# iorx62n register map
Registers are 8-bit, access not given, no defined reset value unless marked. A register's access mark holds for its fields unless they carry their own. Addresses are absolute; registers are grouped by the start of their names; [hi:lo] are bit positions; {n}, {i} and the like mark numbered series; 'fields as' and 'values as' point back to an identical list.

## SFR (part 2 of 3)
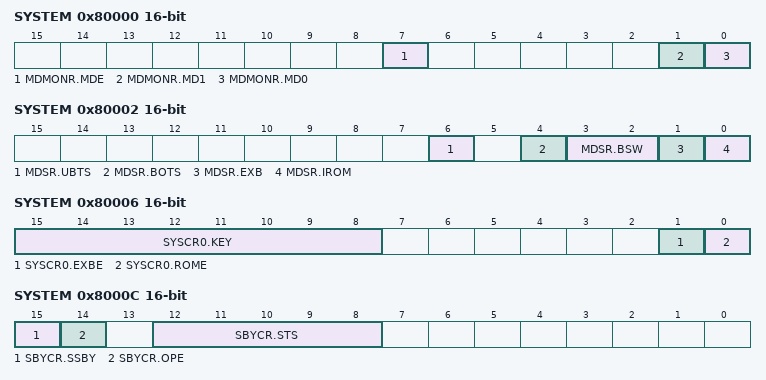
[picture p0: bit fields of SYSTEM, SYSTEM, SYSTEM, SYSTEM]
0x80000 SYSTEM 16-bit
  [7] MDMONR.MDE, [1] MDMONR.MD1, [0] MDMONR.MD0
0x80002 SYSTEM 16-bit
  [6] MDSR.UBTS, [4] MDSR.BOTS, [3:2] MDSR.BSW, [1] MDSR.EXB, [0] MDSR.IROM
0x80006 SYSTEM 16-bit
  [15:8] SYSCR0.KEY, [1] SYSCR0.EXBE, [0] SYSCR0.ROME
0x80008 SYSTEM 16-bit
  [0] SYSCR1.RAME
0x8000C SYSTEM 16-bit
  [15] SBYCR.SSBY, [14] SBYCR.OPE, [12:8] SBYCR.STS
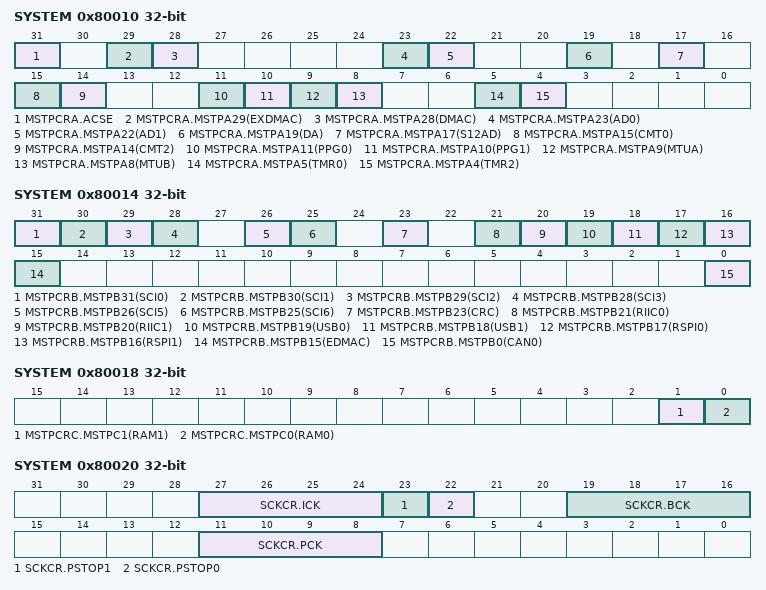
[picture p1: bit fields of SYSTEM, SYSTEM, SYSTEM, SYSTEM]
0x80010 SYSTEM 32-bit
  [31] MSTPCRA.ACSE, [29] MSTPCRA.MSTPA29(EXDMAC), [28] MSTPCRA.MSTPA28(DMAC), [23] MSTPCRA.MSTPA23(AD0), [22] MSTPCRA.MSTPA22(AD1), [19] MSTPCRA.MSTPA19(DA), [17] MSTPCRA.MSTPA17(S12AD), [15] MSTPCRA.MSTPA15(CMT0), [14] MSTPCRA.MSTPA14(CMT2), [11] MSTPCRA.MSTPA11(PPG0), [10] MSTPCRA.MSTPA10(PPG1), [9] MSTPCRA.MSTPA9(MTUA), [8] MSTPCRA.MSTPA8(MTUB), [5] MSTPCRA.MSTPA5(TMR0), [4] MSTPCRA.MSTPA4(TMR2)
0x80014 SYSTEM 32-bit
  [31] MSTPCRB.MSTPB31(SCI0), [30] MSTPCRB.MSTPB30(SCI1), [29] MSTPCRB.MSTPB29(SCI2), [28] MSTPCRB.MSTPB28(SCI3), [26] MSTPCRB.MSTPB26(SCI5), [25] MSTPCRB.MSTPB25(SCI6), [23] MSTPCRB.MSTPB23(CRC), [21] MSTPCRB.MSTPB21(RIIC0), [20] MSTPCRB.MSTPB20(RIIC1), [19] MSTPCRB.MSTPB19(USB0), [18] MSTPCRB.MSTPB18(USB1), [17] MSTPCRB.MSTPB17(RSPI0), [16] MSTPCRB.MSTPB16(RSPI1), [15] MSTPCRB.MSTPB15(EDMAC), [0] MSTPCRB.MSTPB0(CAN0)
0x80018 SYSTEM 32-bit
  [1] MSTPCRC.MSTPC1(RAM1), [0] MSTPCRC.MSTPC0(RAM0)
0x80020 SYSTEM 32-bit
  [27:24] SCKCR.ICK, [23] SCKCR.PSTOP1, [22] SCKCR.PSTOP0, [19:16] SCKCR.BCK, [11:8] SCKCR.PCK
0x80030 SYSTEM
  [0] BCKCR.BCLKDIV
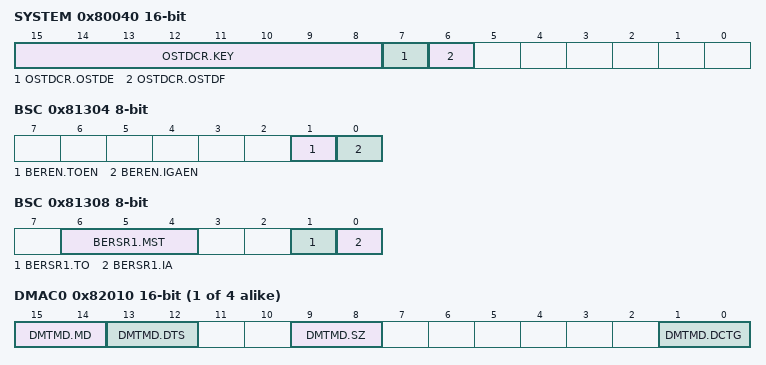
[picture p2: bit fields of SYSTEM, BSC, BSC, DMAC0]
0x80040 SYSTEM 16-bit
  [15:8] OSTDCR.KEY, [7] OSTDCR.OSTDE, [6] OSTDCR.OSTDF
0x81300 BSC
  [0] BERCLR.STSCLR
0x81304 BSC
  [1] BEREN.TOEN, [0] BEREN.IGAEN
0x81308 BSC
  [6:4] BERSR1.MST, [1] BERSR1.TO, [0] BERSR1.IA
0x8130A BSC 16-bit
  [15:3] BERSR2.ADDR
{0x82010+0x40*i} DMAC{i} 16-bit (i=0..3)
  [15:14] DMTMD.MD, [13:12] DMTMD.DTS, [9:8] DMTMD.SZ, [1:0] DMTMD.DCTG
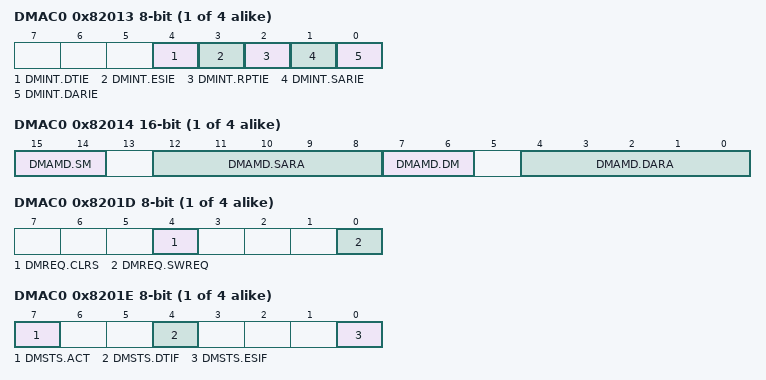
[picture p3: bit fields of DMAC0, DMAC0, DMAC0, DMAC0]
{0x82013+0x40*i} DMAC{i} (i=0..3)
  [4] DMINT.DTIE, [3] DMINT.ESIE, [2] DMINT.RPTIE, [1] DMINT.SARIE, [0] DMINT.DARIE
{0x82014+0x40*i} DMAC{i} 16-bit (i=0..3)
  [15:14] DMAMD.SM, [12:8] DMAMD.SARA, [7:6] DMAMD.DM, [4:0] DMAMD.DARA
{0x8201C+0x40*i} DMAC{i} (i=0..3)
  [0] DMCNT.DTE
{0x8201D+0x40*i} DMAC{i} (i=0..3)
  [4] DMREQ.CLRS, [0] DMREQ.SWREQ
{0x8201E+0x40*i} DMAC{i} (i=0..3)
  [7] DMSTS.ACT, [4] DMSTS.DTIF, [0] DMSTS.ESIF
{0x8201F+0x40*i} DMAC{i} (i=0..3)
  [0] DMCSL.DISEL
0x82200 DMAC
  [0] DMAST.DMST
0x82400 DTC
  [4] DTCCR.RRS
0x82408 DTC
  [0] DTCADMOD.SHORT
0x8240C DTC
  [0] DTCST.DTCST
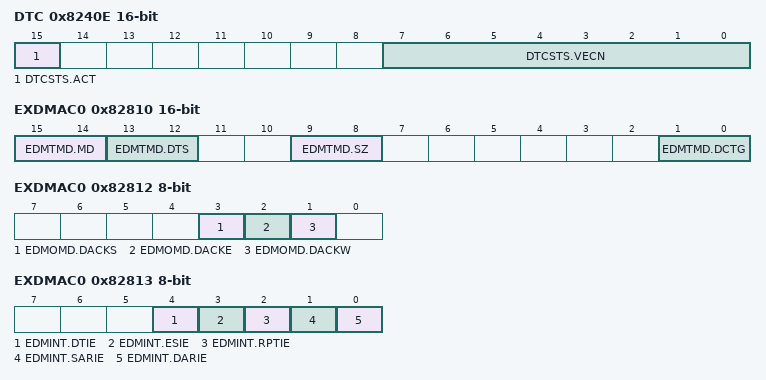
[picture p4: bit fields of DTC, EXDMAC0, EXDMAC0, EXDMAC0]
0x8240E DTC 16-bit
  [15] DTCSTS.ACT, [7:0] DTCSTS.VECN
0x82810 EXDMAC0 16-bit
  [15:14] EDMTMD.MD, [13:12] EDMTMD.DTS, [9:8] EDMTMD.SZ, [1:0] EDMTMD.DCTG
0x82812 EXDMAC0
  [3] EDMOMD.DACKS, [2] EDMOMD.DACKE, [1] EDMOMD.DACKW
0x82813 EXDMAC0
  [4] EDMINT.DTIE, [3] EDMINT.ESIE, [2] EDMINT.RPTIE, [1] EDMINT.SARIE, [0] EDMINT.DARIE
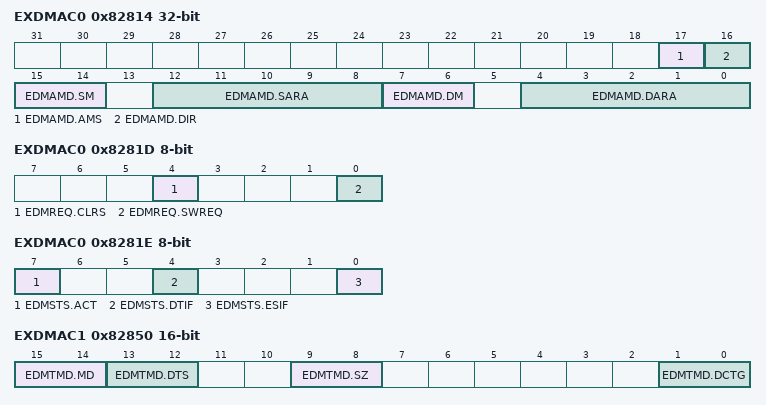
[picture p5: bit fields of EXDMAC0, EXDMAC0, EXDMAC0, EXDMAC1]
0x82814 EXDMAC0 32-bit
  [17] EDMAMD.AMS, [16] EDMAMD.DIR, [15:14] EDMAMD.SM, [12:8] EDMAMD.SARA, [7:6] EDMAMD.DM, [4:0] EDMAMD.DARA
0x8281C EXDMAC0
  [0] EDMCNT.DTE
0x8281D EXDMAC0
  [4] EDMREQ.CLRS, [0] EDMREQ.SWREQ
0x8281E EXDMAC0
  [7] EDMSTS.ACT, [4] EDMSTS.DTIF, [0] EDMSTS.ESIF
0x82820 EXDMAC0
  [1:0] EDMRMD.DREQS
0x82821 EXDMAC0
  [0] EDMERF.EREQ
0x82822 EXDMAC0
  [0] EDMPRF.PREQ
0x82850 EXDMAC1 16-bit
  fields as EXDMAC0
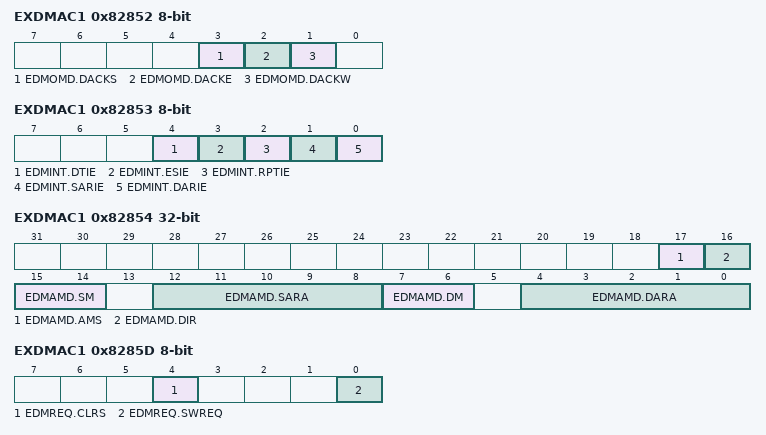
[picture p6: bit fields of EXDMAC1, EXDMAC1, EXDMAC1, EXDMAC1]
0x82852 EXDMAC1
  [3] EDMOMD.DACKS, [2] EDMOMD.DACKE, [1] EDMOMD.DACKW
0x82853 EXDMAC1
  [4] EDMINT.DTIE, [3] EDMINT.ESIE, [2] EDMINT.RPTIE, [1] EDMINT.SARIE, [0] EDMINT.DARIE
0x82854 EXDMAC1 32-bit
  [17] EDMAMD.AMS, [16] EDMAMD.DIR, [15:14] EDMAMD.SM, [12:8] EDMAMD.SARA, [7:6] EDMAMD.DM, [4:0] EDMAMD.DARA
0x8285C EXDMAC1
  [0] EDMCNT.DTE
0x8285D EXDMAC1
  [4] EDMREQ.CLRS, [0] EDMREQ.SWREQ
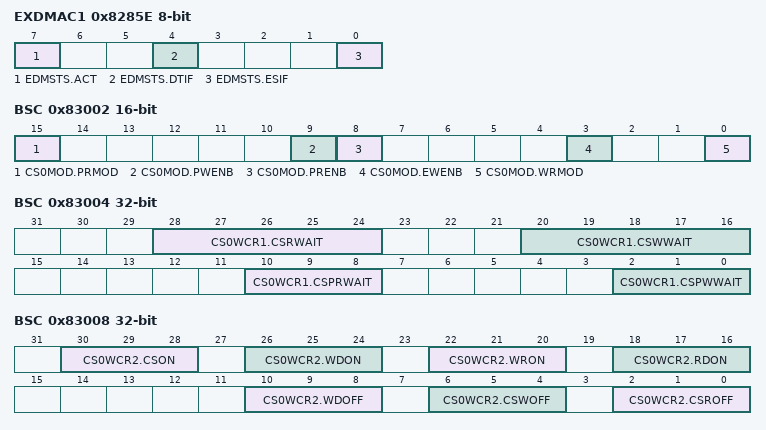
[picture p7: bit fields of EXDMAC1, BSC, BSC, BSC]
0x8285E EXDMAC1
  [7] EDMSTS.ACT, [4] EDMSTS.DTIF, [0] EDMSTS.ESIF
0x82860 EXDMAC1
  [1:0] EDMRMD.DREQS
0x82861 EXDMAC1
  [0] EDMERF.EREQ
0x82862 EXDMAC1
  [0] EDMPRF.PREQ
0x82A00 EXDMAC
  [0] EDMAST.DMST
0x83002 BSC 16-bit
  [15] CS0MOD.PRMOD, [9] CS0MOD.PWENB, [8] CS0MOD.PRENB, [3] CS0MOD.EWENB, [0] CS0MOD.WRMOD
0x83004 BSC 32-bit
  [28:24] CS0WCR1.CSRWAIT, [20:16] CS0WCR1.CSWWAIT, [10:8] CS0WCR1.CSPRWAIT, [2:0] CS0WCR1.CSPWWAIT
0x83008 BSC 32-bit
  [30:28] CS0WCR2.CSON, [26:24] CS0WCR2.WDON, [22:20] CS0WCR2.WRON, [18:16] CS0WCR2.RDON, [10:8] CS0WCR2.WDOFF, [6:4] CS0WCR2.CSWOFF, [2:0] CS0WCR2.CSROFF
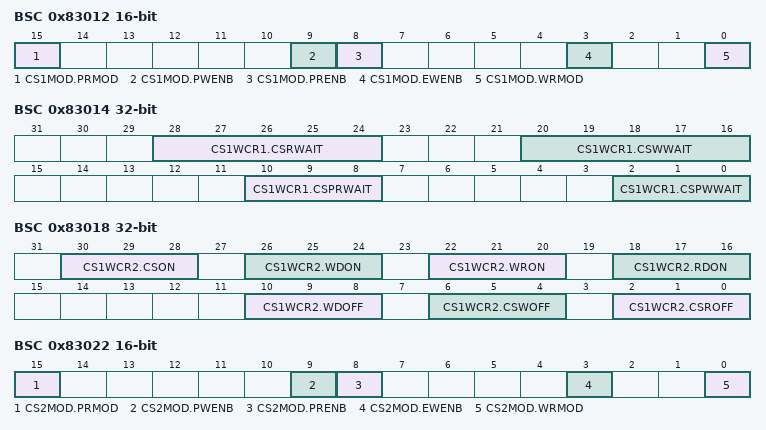
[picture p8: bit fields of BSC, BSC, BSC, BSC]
0x83012 BSC 16-bit
  [15] CS1MOD.PRMOD, [9] CS1MOD.PWENB, [8] CS1MOD.PRENB, [3] CS1MOD.EWENB, [0] CS1MOD.WRMOD
0x83014 BSC 32-bit
  [28:24] CS1WCR1.CSRWAIT, [20:16] CS1WCR1.CSWWAIT, [10:8] CS1WCR1.CSPRWAIT, [2:0] CS1WCR1.CSPWWAIT
0x83018 BSC 32-bit
  [30:28] CS1WCR2.CSON, [26:24] CS1WCR2.WDON, [22:20] CS1WCR2.WRON, [18:16] CS1WCR2.RDON, [10:8] CS1WCR2.WDOFF, [6:4] CS1WCR2.CSWOFF, [2:0] CS1WCR2.CSROFF
0x83022 BSC 16-bit
  [15] CS2MOD.PRMOD, [9] CS2MOD.PWENB, [8] CS2MOD.PRENB, [3] CS2MOD.EWENB, [0] CS2MOD.WRMOD
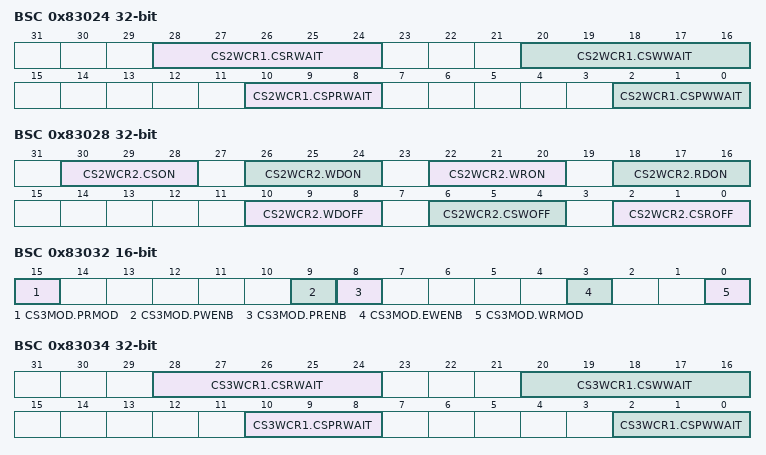
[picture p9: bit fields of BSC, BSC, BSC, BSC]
0x83024 BSC 32-bit
  [28:24] CS2WCR1.CSRWAIT, [20:16] CS2WCR1.CSWWAIT, [10:8] CS2WCR1.CSPRWAIT, [2:0] CS2WCR1.CSPWWAIT
0x83028 BSC 32-bit
  [30:28] CS2WCR2.CSON, [26:24] CS2WCR2.WDON, [22:20] CS2WCR2.WRON, [18:16] CS2WCR2.RDON, [10:8] CS2WCR2.WDOFF, [6:4] CS2WCR2.CSWOFF, [2:0] CS2WCR2.CSROFF
0x83032 BSC 16-bit
  [15] CS3MOD.PRMOD, [9] CS3MOD.PWENB, [8] CS3MOD.PRENB, [3] CS3MOD.EWENB, [0] CS3MOD.WRMOD
0x83034 BSC 32-bit
  [28:24] CS3WCR1.CSRWAIT, [20:16] CS3WCR1.CSWWAIT, [10:8] CS3WCR1.CSPRWAIT, [2:0] CS3WCR1.CSPWWAIT
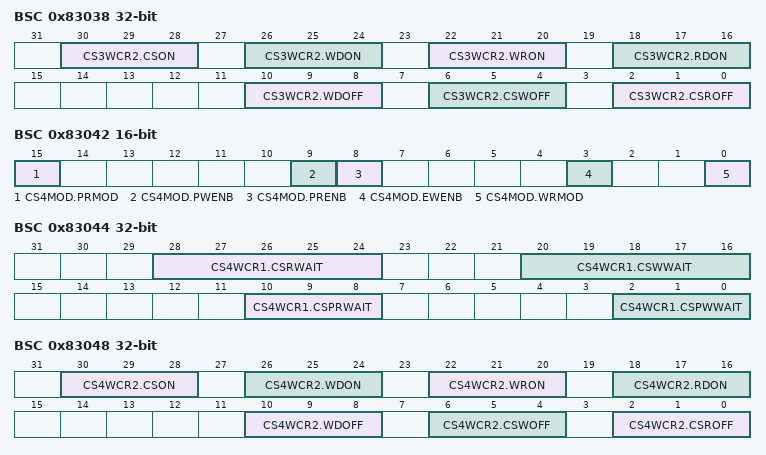
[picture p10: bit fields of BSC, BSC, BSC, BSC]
0x83038 BSC 32-bit
  [30:28] CS3WCR2.CSON, [26:24] CS3WCR2.WDON, [22:20] CS3WCR2.WRON, [18:16] CS3WCR2.RDON, [10:8] CS3WCR2.WDOFF, [6:4] CS3WCR2.CSWOFF, [2:0] CS3WCR2.CSROFF
0x83042 BSC 16-bit
  [15] CS4MOD.PRMOD, [9] CS4MOD.PWENB, [8] CS4MOD.PRENB, [3] CS4MOD.EWENB, [0] CS4MOD.WRMOD
0x83044 BSC 32-bit
  [28:24] CS4WCR1.CSRWAIT, [20:16] CS4WCR1.CSWWAIT, [10:8] CS4WCR1.CSPRWAIT, [2:0] CS4WCR1.CSPWWAIT
0x83048 BSC 32-bit
  [30:28] CS4WCR2.CSON, [26:24] CS4WCR2.WDON, [22:20] CS4WCR2.WRON, [18:16] CS4WCR2.RDON, [10:8] CS4WCR2.WDOFF, [6:4] CS4WCR2.CSWOFF, [2:0] CS4WCR2.CSROFF
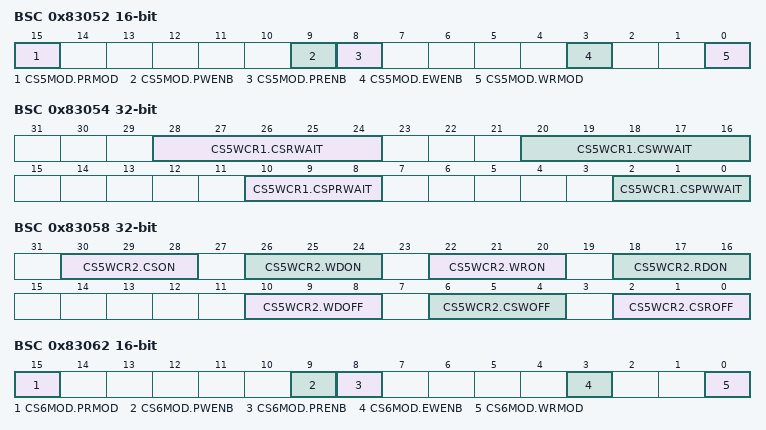
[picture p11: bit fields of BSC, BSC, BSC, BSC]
0x83052 BSC 16-bit
  [15] CS5MOD.PRMOD, [9] CS5MOD.PWENB, [8] CS5MOD.PRENB, [3] CS5MOD.EWENB, [0] CS5MOD.WRMOD
0x83054 BSC 32-bit
  [28:24] CS5WCR1.CSRWAIT, [20:16] CS5WCR1.CSWWAIT, [10:8] CS5WCR1.CSPRWAIT, [2:0] CS5WCR1.CSPWWAIT
0x83058 BSC 32-bit
  [30:28] CS5WCR2.CSON, [26:24] CS5WCR2.WDON, [22:20] CS5WCR2.WRON, [18:16] CS5WCR2.RDON, [10:8] CS5WCR2.WDOFF, [6:4] CS5WCR2.CSWOFF, [2:0] CS5WCR2.CSROFF
0x83062 BSC 16-bit
  [15] CS6MOD.PRMOD, [9] CS6MOD.PWENB, [8] CS6MOD.PRENB, [3] CS6MOD.EWENB, [0] CS6MOD.WRMOD
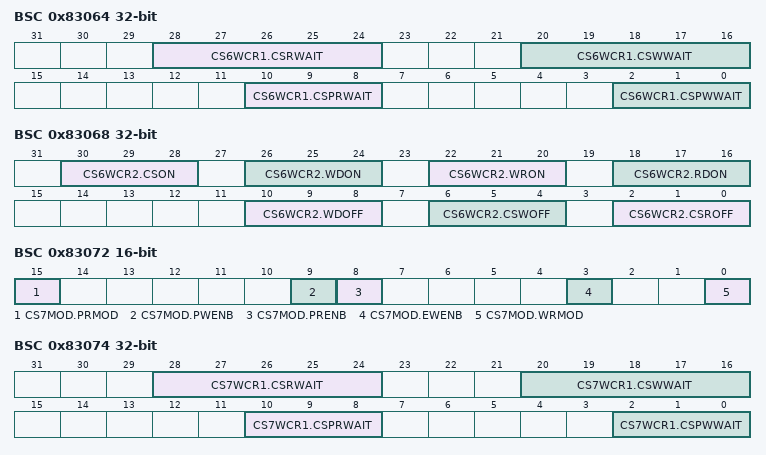
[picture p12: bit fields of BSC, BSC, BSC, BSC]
0x83064 BSC 32-bit
  [28:24] CS6WCR1.CSRWAIT, [20:16] CS6WCR1.CSWWAIT, [10:8] CS6WCR1.CSPRWAIT, [2:0] CS6WCR1.CSPWWAIT
0x83068 BSC 32-bit
  [30:28] CS6WCR2.CSON, [26:24] CS6WCR2.WDON, [22:20] CS6WCR2.WRON, [18:16] CS6WCR2.RDON, [10:8] CS6WCR2.WDOFF, [6:4] CS6WCR2.CSWOFF, [2:0] CS6WCR2.CSROFF
0x83072 BSC 16-bit
  [15] CS7MOD.PRMOD, [9] CS7MOD.PWENB, [8] CS7MOD.PRENB, [3] CS7MOD.EWENB, [0] CS7MOD.WRMOD
0x83074 BSC 32-bit
  [28:24] CS7WCR1.CSRWAIT, [20:16] CS7WCR1.CSWWAIT, [10:8] CS7WCR1.CSPRWAIT, [2:0] CS7WCR1.CSPWWAIT
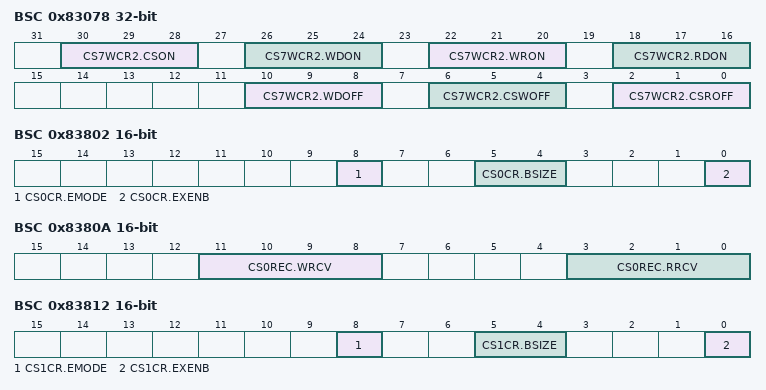
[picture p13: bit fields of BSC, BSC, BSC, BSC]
0x83078 BSC 32-bit
  [30:28] CS7WCR2.CSON, [26:24] CS7WCR2.WDON, [22:20] CS7WCR2.WRON, [18:16] CS7WCR2.RDON, [10:8] CS7WCR2.WDOFF, [6:4] CS7WCR2.CSWOFF, [2:0] CS7WCR2.CSROFF
0x83802 BSC 16-bit
  [8] CS0CR.EMODE, [5:4] CS0CR.BSIZE, [0] CS0CR.EXENB
0x8380A BSC 16-bit
  [11:8] CS0REC.WRCV, [3:0] CS0REC.RRCV
0x83812 BSC 16-bit
  [8] CS1CR.EMODE, [5:4] CS1CR.BSIZE, [0] CS1CR.EXENB
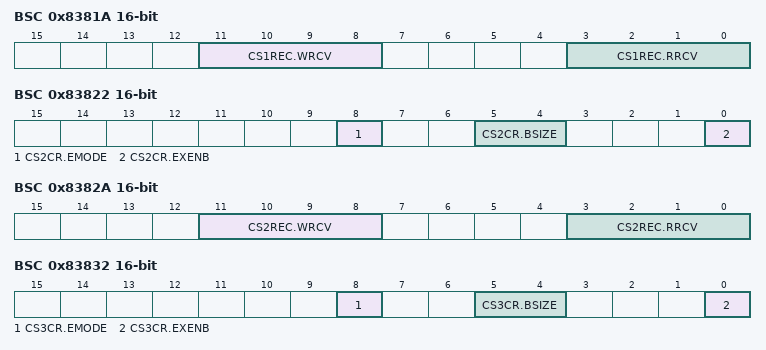
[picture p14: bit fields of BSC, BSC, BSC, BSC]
0x8381A BSC 16-bit
  [11:8] CS1REC.WRCV, [3:0] CS1REC.RRCV
0x83822 BSC 16-bit
  [8] CS2CR.EMODE, [5:4] CS2CR.BSIZE, [0] CS2CR.EXENB
0x8382A BSC 16-bit
  [11:8] CS2REC.WRCV, [3:0] CS2REC.RRCV
0x83832 BSC 16-bit
  [8] CS3CR.EMODE, [5:4] CS3CR.BSIZE, [0] CS3CR.EXENB
0x8383A BSC 16-bit
  [11:8] CS3REC.WRCV, [3:0] CS3REC.RRCV
0x83842 BSC 16-bit
  [8] CS4CR.EMODE, [5:4] CS4CR.BSIZE, [0] CS4CR.EXENB
0x8384A BSC 16-bit
  [11:8] CS4REC.WRCV, [3:0] CS4REC.RRCV
0x83852 BSC 16-bit
  [8] CS5CR.EMODE, [5:4] CS5CR.BSIZE, [0] CS5CR.EXENB
0x8385A BSC 16-bit
  [11:8] CS5REC.WRCV, [3:0] CS5REC.RRCV
0x83862 BSC 16-bit
  [8] CS6CR.EMODE, [5:4] CS6CR.BSIZE, [0] CS6CR.EXENB
0x8386A BSC 16-bit
  [11:8] CS6REC.WRCV, [3:0] CS6REC.RRCV
0x83872 BSC 16-bit
  [8] CS7CR.EMODE, [5:4] CS7CR.BSIZE, [0] CS7CR.EXENB
0x8387A BSC 16-bit
  [11:8] CS7REC.WRCV, [3:0] CS7REC.RRCV
0x83C00 BSC
  [5:4] SDCCR.BSIZE, [0] SDCCR.EXENB
0x83C01 BSC
  [0] SDCMOD.EMODE
0x83C02 BSC
  [0] SDAMOD.BE
0x83C10 BSC
  [0] SDSELF.SFEN
0x83C14 BSC 16-bit
  [15:12] SDRFCR.REFW, [11:0] SDRFCR.RFC
0x83C16 BSC
  [0] SDRFEN.RFEN
0x83C20 BSC
  [0] SDICR.INIRQ
0x83C24 BSC 16-bit
  [10:8] SDIR.PRC, [7:4] SDIR.ARFC, [3:0] SDIR.ARFI
0x83C40 BSC
  [1:0] SDADR.MXC
0x83C44 BSC 32-bit
  [18:16] SDTR.RAS, [13:12] SDTR.RCD, [11:9] SDTR.RP, [8] SDTR.WR, [2:0] SDTR.CL
0x83C48 BSC 16-bit
  [14:0] SDMOD.MR
0x83C50 BSC
  [4] SDSR.SRFST, [3] SDSR.INIST, [0] SDSR.MRSST
0x86400 MPU 32-bit
  [31:4] RSPAGE0.RSPN
0x86404 MPU 32-bit
  [31:4] REPAGE0.REPN, [3:1] REPAGE0.UAC, [0] REPAGE0.V
0x86408 MPU 32-bit
  [31:4] RSPAGE1.RSPN
0x8640C MPU 32-bit
  [31:4] REPAGE1.REPN, [3:1] REPAGE1.UAC, [0] REPAGE1.V
0x86410 MPU 32-bit
  [31:4] RSPAGE2.RSPN
0x86414 MPU 32-bit
  [31:4] REPAGE2.REPN, [3:1] REPAGE2.UAC, [0] REPAGE2.V
0x86418 MPU 32-bit
  [31:4] RSPAGE3.RSPN
0x8641C MPU 32-bit
  [31:4] REPAGE3.REPN, [3:1] REPAGE3.UAC, [0] REPAGE3.V
0x86420 MPU 32-bit
  [31:4] RSPAGE4.RSPN
0x86424 MPU 32-bit
  [31:4] REPAGE4.REPN, [3:1] REPAGE4.UAC, [0] REPAGE4.V
0x86428 MPU 32-bit
  [31:4] RSPAGE5.RSPN
0x8642C MPU 32-bit
  [31:4] REPAGE5.REPN, [3:1] REPAGE5.UAC, [0] REPAGE5.V
0x86430 MPU 32-bit
  [31:4] RSPAGE6.RSPN
0x86434 MPU 32-bit
  [31:4] REPAGE6.REPN, [3:1] REPAGE6.UAC, [0] REPAGE6.V
0x86438 MPU 32-bit
  [31:4] RSPAGE7.RSPN
0x8643C MPU 32-bit
  [31:4] REPAGE7.REPN, [3:1] REPAGE7.UAC, [0] REPAGE7.V
0x86500 MPU 32-bit
  [0] MPEN.MPEN
0x86504 MPU 32-bit
  [3:1] MPBAC.UBAC
0x86508 MPU 32-bit
  [0] MPECLR.CLR
0x8650C MPU 32-bit
  [2] MPESTS.DRW, [1] MPESTS.DA, [0] MPESTS.IA
0x86514 MPU 32-bit
  [31:0] MPDEA.DEA
0x86520 MPU 32-bit
  [31:0] MPSA.SA
0x86524 MPU 16-bit
  [0] MPOPS.S
0x86526 MPU 16-bit
  [0] MPOPI.INV
0x86528 MPU 32-bit
  [23:16] MHITI.HITI, [3:1] MHITI.UHACI
0x8652C MPU 32-bit
  [23:16] MHITD.HITD, [3:1] MHITD.UHACD
0x87000 ICU
  [0] IR[0].IR
0x87001 ICU
  [0] IR[1].IR
0x87002 ICU
  [0] IR[2].IR
0x87003 ICU
  [0] IR[3].IR
0x87004 ICU
  [0] IR[4].IR
0x87005 ICU
  [0] IR[5].IR
0x87006 ICU
  [0] IR[6].IR
0x87007 ICU
  [0] IR[7].IR
0x87008 ICU
  [0] IR[8].IR
0x87009 ICU
  [0] IR[9].IR
0x8700A ICU
  [0] IR[10].IR
0x8700B ICU
  [0] IR[11].IR
0x8700C ICU
  [0] IR[12].IR
0x8700D ICU
  [0] IR[13].IR
0x8700E ICU
  [0] IR[14].IR
0x8700F ICU
  [0] IR[15].IR
0x87010 ICU
  [0] IR[16](BSC,BUSERR).IR
0x87011 ICU
  [0] IR[17].IR
0x87012 ICU
  [0] IR[18].IR
0x87013 ICU
  [0] IR[19].IR
0x87014 ICU
  [0] IR[20].IR
0x87015 ICU
  [0] IR[21](FCU,FIFERR).IR
0x87016 ICU
  [0] IR[22].IR
0x87017 ICU
  [0] IR[23](FCU,FRDYI).IR
0x87018 ICU
  [0] IR[24].IR
0x87019 ICU
  [0] IR[25].IR
0x8701A ICU
  [0] IR[26].IR
0x8701B ICU
  [0] IR[27](ICU,SWINT).IR
0x8701C ICU
  [0] IR[28](CMT0,CMI0).IR
0x8701D ICU
  [0] IR[29](CMT1,CMI1).IR
0x8701E ICU
  [0] IR[30](CMT2,CMI2).IR
0x8701F ICU
  [0] IR[31](CMT3,CMI3).IR
0x87020 ICU
  [0] IR[32](ETHER,EINT).IR
0x87021 ICU
  [0] IR[33].IR
0x87022 ICU
  [0] IR[34].IR
0x87023 ICU
  [0] IR[35].IR
0x87024 ICU
  [0] IR[36](USB0,D0FIFO0).IR
0x87025 ICU
  [0] IR[37](USB0,D1FIFO0).IR
0x87026 ICU
  [0] IR[38](USB0,USBI0).IR
0x87027 ICU
  [0] IR[39].IR
0x87028 ICU
  [0] IR[40](USB1,D0FIFO1).IR
0x87029 ICU
  [0] IR[41](USB1,D1FIFO1).IR
0x8702A ICU
  [0] IR[42](USB1,USBI1).IR
0x8702B ICU
  [0] IR[43].IR
0x8702C ICU
  [0] IR[44](RSPI0,SPEI0).IR
0x8702D ICU
  [0] IR[45](RSPI0,SPRI0).IR
0x8702E ICU
  [0] IR[46](RSPI0,SPTI0).IR
0x8702F ICU
  [0] IR[47](RSPI0,SPII0).IR
0x87030 ICU
  [0] IR[48](RSPI1,SPEI1).IR
0x87031 ICU
  [0] IR[49](RSPI1,SPRI1).IR
0x87032 ICU
  [0] IR[50](RSPI1,SPTI1).IR
0x87033 ICU
  [0] IR[51](RSPI1,SPII1).IR
0x87034 ICU
  [0] IR[52].IR
0x87035 ICU
  [0] IR[53].IR
0x87036 ICU
  [0] IR[54].IR
0x87037 ICU
  [0] IR[55].IR
0x87038 ICU
  [0] IR[56](CAN0,ERS0).IR
0x87039 ICU
  [0] IR[57](CAN0,RXF0).IR
0x8703A ICU
  [0] IR[58](CAN0,TXF0).IR
0x8703B ICU
  [0] IR[59](CAN0,RXM0).IR
0x8703C ICU
  [0] IR[60](CAN0,TXM0).IR
0x8703D ICU
  [0] IR[61].IR
0x8703E ICU
  [0] IR[62](RTC,PRD).IR
0x8703F ICU
  [0] IR[63](RTC,CUP).IR
0x87040 ICU
  [0] IR[64](ICU,IRQ0).IR
0x87041 ICU
  [0] IR[65](ICU,IRQ1).IR
0x87042 ICU
  [0] IR[66](ICU,IRQ2).IR
0x87043 ICU
  [0] IR[67](ICU,IRQ3).IR
0x87044 ICU
  [0] IR[68](ICU,IRQ4).IR
0x87045 ICU
  [0] IR[69](ICU,IRQ5).IR
0x87046 ICU
  [0] IR[70](ICU,IRQ6).IR
0x87047 ICU
  [0] IR[71](ICU,IRQ7).IR
0x87048 ICU
  [0] IR[72](ICU,IRQ8).IR
0x87049 ICU
  [0] IR[73](ICU,IRQ9).IR
0x8704A ICU
  [0] IR[74](ICU,IRQ10).IR
0x8704B ICU
  [0] IR[75](ICU,IRQ11).IR
0x8704C ICU
  [0] IR[76](ICU,IRQ12).IR
0x8704D ICU
  [0] IR[77](ICU,IRQ13).IR
0x8704E ICU
  [0] IR[78](ICU,IRQ14).IR
0x8704F ICU
  [0] IR[79](ICU,IRQ15).IR
0x87050 ICU
  [0] IR[80].IR
0x87051 ICU
  [0] IR[81].IR
0x87052 ICU
  [0] IR[82].IR
0x87053 ICU
  [0] IR[83].IR
0x87054 ICU
  [0] IR[84].IR
0x87055 ICU
  [0] IR[85].IR
0x87056 ICU
  [0] IR[86].IR
0x87057 ICU
  [0] IR[87].IR
0x87058 ICU
  [0] IR[88].IR
0x87059 ICU
  [0] IR[89].IR
0x8705A ICU
  [0] IR[90](USB,USBR0).IR
0x8705B ICU
  [0] IR[91](USB,USBR1).IR
0x8705C ICU
  [0] IR[92](RTC,ALM).IR
0x8705D ICU
  [0] IR[93].IR
0x8705E ICU
  [0] IR[94].IR
0x8705F ICU
  [0] IR[95].IR
0x87060 ICU
  [0] IR[96](WDT,WOVI).IR
0x87061 ICU
  [0] IR[97].IR
0x87062 ICU
  [0] IR[98](AD0,ADI0).IR
0x87063 ICU
  [0] IR[99](AD1,ADI1).IR
0x87064 ICU
  [0] IR[100].IR
0x87065 ICU
  [0] IR[101].IR
0x87066 ICU
  [0] IR[102](S12AD,ADI).IR
0x87067 ICU
  [0] IR[103].IR
0x87068 ICU
  [0] IR[104].IR
0x87069 ICU
  [0] IR[105].IR
0x8706A ICU
  [0] IR[106].IR
0x8706B ICU
  [0] IR[107].IR
0x8706C ICU
  [0] IR[108].IR
0x8706D ICU
  [0] IR[109].IR
0x8706E ICU
  [0] IR[110].IR
0x8706F ICU
  [0] IR[111].IR
0x87070 ICU
  [0] IR[112].IR
0x87071 ICU
  [0] IR[113].IR
0x87072 ICU
  [0] IR[114](MTU0,TGIA0).IR
0x87073 ICU
  [0] IR[115](MTU0,TGIB0).IR
0x87074 ICU
  [0] IR[116](MTU0,TGIC0).IR
0x87075 ICU
  [0] IR[117](MTU0,TGID0).IR
0x87076 ICU
  [0] IR[118](MTU0,TCIV0).IR
0x87077 ICU
  [0] IR[119](MTU0,TGIE0).IR
0x87078 ICU
  [0] IR[120](MTU0,TGIF0).IR
0x87079 ICU
  [0] IR[121](MTU1,TGIA1).IR
0x8707A ICU
  [0] IR[122](MTU1,TGIB1).IR
0x8707B ICU
  [0] IR[123](MTU1,TCIV1).IR
0x8707C ICU
  [0] IR[124](MTU1,TCIU1).IR
0x8707D ICU
  [0] IR[125](MTU2,TGIA2).IR
0x8707E ICU
  [0] IR[126](MTU2,TGIB2).IR
0x8707F ICU
  [0] IR[127](MTU2,TCIV2).IR
0x87080 ICU
  [0] IR[128](MTU2,TCIU2).IR
0x87081 ICU
  [0] IR[129](MTU3,TGIA3).IR
0x87082 ICU
  [0] IR[130](MTU3,TGIB3).IR
0x87083 ICU
  [0] IR[131](MTU3,TGIC3).IR
0x87084 ICU
  [0] IR[132](MTU3,TGID3).IR
0x87085 ICU
  [0] IR[133](MTU3,TCIV3).IR
0x87086 ICU
  [0] IR[134](MTU4,TGIA4).IR
0x87087 ICU
  [0] IR[135](MTU4,TGIB4).IR
0x87088 ICU
  [0] IR[136](MTU4,TGIC4).IR
0x87089 ICU
  [0] IR[137](MTU4,TGID4).IR
0x8708A ICU
  [0] IR[138](MTU4,TCIV4).IR
0x8708B ICU
  [0] IR[139](MTU5,TGIU5).IR
0x8708C ICU
  [0] IR[140](MTU5,TGIV5).IR
0x8708D ICU
  [0] IR[141](MTU5,TGIW5).IR
0x8708E ICU
  [0] IR[142](MTU6,TGIA6).IR
0x8708F ICU
  [0] IR[143](MTU6,TGIB6).IR
0x87090 ICU
  [0] IR[144](MTU6,TGIC6).IR
0x87091 ICU
  [0] IR[145](MTU6,TGID6).IR
0x87092 ICU
  [0] IR[146](MTU6,TCIV6).IR
0x87093 ICU
  [0] IR[147](MTU6,TGIE6).IR
0x87094 ICU
  [0] IR[148](MTU6,TGIF6).IR
0x87095 ICU
  [0] IR[149](MTU7,TGIA7).IR
0x87096 ICU
  [0] IR[150](MTU7,TGIB7).IR
0x87097 ICU
  [0] IR[151](MTU7,TCIV7).IR
0x87098 ICU
  [0] IR[152](MTU7,TCIU7).IR
0x87099 ICU
  [0] IR[153](MTU8,TGIA8).IR
0x8709A ICU
  [0] IR[154](MTU8,TGIB8).IR
0x8709B ICU
  [0] IR[155](MTU8,TCIV8).IR
0x8709C ICU
  [0] IR[156](MTU8,TCIU8).IR
0x8709D ICU
  [0] IR[157](MTU9,TGIA9).IR
0x8709E ICU
  [0] IR[158](MTU9,TGIB9).IR
0x8709F ICU
  [0] IR[159](MTU9,TGIC9).IR
0x870A0 ICU
  [0] IR[160](MTU9,TGID9).IR
0x870A1 ICU
  [0] IR[161](MTU9,TCIV9).IR
0x870A2 ICU
  [0] IR[162](MTU10,TGIA10).IR
0x870A3 ICU
  [0] IR[163](MTU10,TGIB10).IR
0x870A4 ICU
  [0] IR[164](MTU10,TGIC10).IR
0x870A5 ICU
  [0] IR[165](MTU10,TGID10).IR
0x870A6 ICU
  [0] IR[166](MTU10,TCIV10).IR
0x870A7 ICU
  [0] IR[167](MTU11,TGIU11).IR
0x870A8 ICU
  [0] IR[168](MTU11,TGIV11).IR
0x870A9 ICU
  [0] IR[169](MTU11,TGIW11).IR
0x870AA ICU
  [0] IR[170](POE,OEI1).IR
0x870AB ICU
  [0] IR[171](POE,OEI2).IR
0x870AC ICU
  [0] IR[172](POE,OEI3).IR
0x870AD ICU
  [0] IR[173](POE,OEI4).IR
0x870AE ICU
  [0] IR[174](TMR0,CMIA0).IR
0x870AF ICU
  [0] IR[175](TMR0,CMIB0).IR
0x870B0 ICU
  [0] IR[176](TMR0,OVI0).IR
0x870B1 ICU
  [0] IR[177](TMR1,CMIA1).IR
0x870B2 ICU
  [0] IR[178](TMR1,CMIB1).IR
0x870B3 ICU
  [0] IR[179](TMR1,OVI1).IR
0x870B4 ICU
  [0] IR[180](TMR2,CMIA2).IR
0x870B5 ICU
  [0] IR[181](TMR2,CMIB2).IR
0x870B6 ICU
  [0] IR[182](TMR2,OVI2).IR
0x870B7 ICU
  [0] IR[183](TMR3,CMIA3).IR
0x870B8 ICU
  [0] IR[184](TMR3,CMIB3).IR
0x870B9 ICU
  [0] IR[185](TMR3,OVI3).IR
0x870BA ICU
  [0] IR[186].IR
0x870BB ICU
  [0] IR[187].IR
0x870BC ICU
  [0] IR[188].IR
0x870BD ICU
  [0] IR[189].IR
0x870BE ICU
  [0] IR[190].IR
0x870BF ICU
  [0] IR[191].IR
0x870C0 ICU
  [0] IR[192].IR
0x870C1 ICU
  [0] IR[193].IR
0x870C2 ICU
  [0] IR[194].IR
0x870C3 ICU
  [0] IR[195].IR
0x870C4 ICU
  [0] IR[196].IR
0x870C5 ICU
  [0] IR[197].IR
0x870C6 ICU
  [0] IR[198](DMAC,DMAC0I).IR
0x870C7 ICU
  [0] IR[199](DMAC,DMAC1I).IR
0x870C8 ICU
  [0] IR[200](DMAC,DMAC2I).IR
0x870C9 ICU
  [0] IR[201](DMAC,DMAC3I).IR
0x870CA ICU
  [0] IR[202](EXDMAC,EXDMAC0I).IR
0x870CB ICU
  [0] IR[203](EXDMAC,EXDMAC1I).IR
0x870CC ICU
  [0] IR[204].IR
0x870CD ICU
  [0] IR[205].IR
0x870CE ICU
  [0] IR[206].IR
0x870CF ICU
  [0] IR[207].IR
0x870D0 ICU
  [0] IR[208].IR
0x870D1 ICU
  [0] IR[209].IR
0x870D2 ICU
  [0] IR[210].IR
0x870D3 ICU
  [0] IR[211].IR
0x870D4 ICU
  [0] IR[212].IR
0x870D5 ICU
  [0] IR[213].IR
0x870D6 ICU
  [0] IR[214](SCI0,ERI0).IR
0x870D7 ICU
  [0] IR[215](SCI0,RXI0).IR
0x870D8 ICU
  [0] IR[216](SCI0,TXI0).IR
0x870D9 ICU
  [0] IR[217](SCI0,TEI0).IR
0x870DA ICU
  [0] IR[218](SCI1,ERI1).IR
0x870DB ICU
  [0] IR[219](SCI1,RXI1).IR
0x870DC ICU
  [0] IR[220](SCI1,TXI1).IR
0x870DD ICU
  [0] IR[221](SCI1,TEI1).IR
0x870DE ICU
  [0] IR[222](SCI2,ERI2).IR
0x870DF ICU
  [0] IR[223](SCI2,RXI2).IR
0x870E0 ICU
  [0] IR[224](SCI2,TXI2).IR
0x870E1 ICU
  [0] IR[225](SCI2,TEI2).IR
0x870E2 ICU
  [0] IR[226](SCI3,ERI3).IR
0x870E3 ICU
  [0] IR[227](SCI3,RXI3).IR
0x870E4 ICU
  [0] IR[228](SCI3,TXI3).IR
0x870E5 ICU
  [0] IR[229](SCI3,TEI3).IR
0x870E6 ICU
  [0] IR[230].IR
0x870E7 ICU
  [0] IR[231].IR
0x870E8 ICU
  [0] IR[232].IR
0x870E9 ICU
  [0] IR[233].IR
0x870EA ICU
  [0] IR[234](SCI5,ERI5).IR
0x870EB ICU
  [0] IR[235](SCI5,RXI5).IR
0x870EC ICU
  [0] IR[236](SCI5,TXI5).IR
0x870ED ICU
  [0] IR[237](SCI5,TEI5).IR
0x870EE ICU
  [0] IR[238](SCI6,ERI6).IR
0x870EF ICU
  [0] IR[239](SCI6,RXI6).IR
0x870F0 ICU
  [0] IR[240](SCI6,TXI6).IR
0x870F1 ICU
  [0] IR[241](SCI6,TEI6).IR
0x870F2 ICU
  [0] IR[242].IR
0x870F3 ICU
  [0] IR[243].IR
0x870F4 ICU
  [0] IR[244].IR
0x870F5 ICU
  [0] IR[245].IR
0x870F6 ICU
  [0] IR[246](RIIC0,ICEEI0).IR
0x870F7 ICU
  [0] IR[247](RIIC0,ICRXI0).IR
0x870F8 ICU
  [0] IR[248](RIIC0,ICTXI0).IR
0x870F9 ICU
  [0] IR[249](RIIC0,ICTEI0).IR
0x870FA ICU
  [0] IR[250](RIIC1,ICEEI1).IR
0x870FB ICU
  [0] IR[251](RIIC1,ICRXI1).IR
0x870FC ICU
  [0] IR[252](RIIC1,ICTXI1).IR
0x870FD ICU
  [0] IR[253].IR
0x87100 ICU
  [0] DTCER[0].DTCE
0x87101 ICU
  [0] DTCER[1].DTCE
0x87102 ICU
  [0] DTCER[2].DTCE
0x87103 ICU
  [0] DTCER[3].DTCE
0x87104 ICU
  [0] DTCER[4].DTCE
0x87105 ICU
  [0] DTCER[5].DTCE
0x87106 ICU
  [0] DTCER[6].DTCE
0x87107 ICU
  [0] DTCER[7].DTCE
0x87108 ICU
  [0] DTCER[8].DTCE
0x87109 ICU
  [0] DTCER[9].DTCE
0x8710A ICU
  [0] DTCER[10].DTCE
0x8710B ICU
  [0] DTCER[11].DTCE
0x8710C ICU
  [0] DTCER[12].DTCE
0x8710D ICU
  [0] DTCER[13].DTCE
0x8710E ICU
  [0] DTCER[14].DTCE
0x8710F ICU
  [0] DTCER[15].DTCE
0x87110 ICU
  [0] DTCER[16](BSC,BUSERR).DTCE
0x87111 ICU
  [0] DTCER[17].DTCE
0x87112 ICU
  [0] DTCER[18].DTCE
0x87113 ICU
  [0] DTCER[19].DTCE
0x87114 ICU
  [0] DTCER[20].DTCE
0x87115 ICU
  [0] DTCER[21](FCU,FIFERR).DTCE
0x87116 ICU
  [0] DTCER[22].DTCE
0x87117 ICU
  [0] DTCER[23](FCU,FRDYI).DTCE
0x87118 ICU
  [0] DTCER[24].DTCE
0x87119 ICU
  [0] DTCER[25].DTCE
0x8711A ICU
  [0] DTCER[26].DTCE
0x8711B ICU
  [0] DTCER[27](ICU,SWINT).DTCE
0x8711C ICU
  [0] DTCER[28](CMT0,CMI0).DTCE
0x8711D ICU
  [0] DTCER[29](CMT1,CMI1).DTCE
0x8711E ICU
  [0] DTCER[30](CMT2,CMI2).DTCE
0x8711F ICU
  [0] DTCER[31](CMT3,CMI3).DTCE
0x87120 ICU
  [0] DTCER[32](ETHER,EINT).DTCE
0x87121 ICU
  [0] DTCER[33].DTCE
0x87122 ICU
  [0] DTCER[34].DTCE
0x87123 ICU
  [0] DTCER[35].DTCE
0x87124 ICU
  [0] DTCER[36](USB0,D0FIFO0).DTCE
0x87125 ICU
  [0] DTCER[37](USB0,D1FIFO0).DTCE
0x87126 ICU
  [0] DTCER[38](USB0,USBI0).DTCE
0x87127 ICU
  [0] DTCER[39].DTCE
0x87128 ICU
  [0] DTCER[40](USB1,D0FIFO1).DTCE
0x87129 ICU
  [0] DTCER[41](USB1,D1FIFO1).DTCE
0x8712A ICU
  [0] DTCER[42](USB1,USBI1).DTCE
0x8712B ICU
  [0] DTCER[43].DTCE
0x8712C ICU
  [0] DTCER[44](RSPI0,SPEI0).DTCE
0x8712D ICU
  [0] DTCER[45](RSPI0,SPRI0).DTCE
0x8712E ICU
  [0] DTCER[46](RSPI0,SPTI0).DTCE
0x8712F ICU
  [0] DTCER[47](RSPI0,SPII0).DTCE
0x87130 ICU
  [0] DTCER[48](RSPI1,SPEI1).DTCE
0x87131 ICU
  [0] DTCER[49](RSPI1,SPRI1).DTCE
0x87132 ICU
  [0] DTCER[50](RSPI1,SPTI1).DTCE
0x87133 ICU
  [0] DTCER[51](RSPI1,SPII1).DTCE
0x87134 ICU
  [0] DTCER[52].DTCE
0x87135 ICU
  [0] DTCER[53].DTCE
0x87136 ICU
  [0] DTCER[54].DTCE
0x87137 ICU
  [0] DTCER[55].DTCE
0x87138 ICU
  [0] DTCER[56](CAN0,ERS0).DTCE
0x87139 ICU
  [0] DTCER[57](CAN0,RXF0).DTCE
0x8713A ICU
  [0] DTCER[58](CAN0,TXF0).DTCE
0x8713B ICU
  [0] DTCER[59](CAN0,RXM0).DTCE
0x8713C ICU
  [0] DTCER[60](CAN0,TXM0).DTCE
0x8713D ICU
  [0] DTCER[61].DTCE
0x8713E ICU
  [0] DTCER[62](RTC,PRD).DTCE
0x8713F ICU
  [0] DTCER[63](RTC,CUP).DTCE
0x87140 ICU
  [0] DTCER[64](ICU,IRQ0).DTCE
0x87141 ICU
  [0] DTCER[65](ICU,IRQ1).DTCE
0x87142 ICU
  [0] DTCER[66](ICU,IRQ2).DTCE
0x87143 ICU
  [0] DTCER[67](ICU,IRQ3).DTCE
0x87144 ICU
  [0] DTCER[68](ICU,IRQ4).DTCE
0x87145 ICU
  [0] DTCER[69](ICU,IRQ5).DTCE
0x87146 ICU
  [0] DTCER[70](ICU,IRQ6).DTCE
0x87147 ICU
  [0] DTCER[71](ICU,IRQ7).DTCE
0x87148 ICU
  [0] DTCER[72](ICU,IRQ8).DTCE
0x87149 ICU
  [0] DTCER[73](ICU,IRQ9).DTCE
0x8714A ICU
  [0] DTCER[74](ICU,IRQ10).DTCE
0x8714B ICU
  [0] DTCER[75](ICU,IRQ11).DTCE
0x8714C ICU
  [0] DTCER[76](ICU,IRQ12).DTCE
0x8714D ICU
  [0] DTCER[77](ICU,IRQ13).DTCE
0x8714E ICU
  [0] DTCER[78](ICU,IRQ14).DTCE
0x8714F ICU
  [0] DTCER[79](ICU,IRQ15).DTCE
0x87150 ICU
  [0] DTCER[80].DTCE
0x87151 ICU
  [0] DTCER[81].DTCE
0x87152 ICU
  [0] DTCER[82].DTCE
0x87153 ICU
  [0] DTCER[83].DTCE
0x87154 ICU
  [0] DTCER[84].DTCE
0x87155 ICU
  [0] DTCER[85].DTCE
0x87156 ICU
  [0] DTCER[86].DTCE
0x87157 ICU
  [0] DTCER[87].DTCE
0x87158 ICU
  [0] DTCER[88].DTCE
0x87159 ICU
  [0] DTCER[89].DTCE
0x8715A ICU
  [0] DTCER[90](USB,USBR0).DTCE
0x8715B ICU
  [0] DTCER[91](USB,USBR1).DTCE
0x8715C ICU
  [0] DTCER[92](RTC,ALM).DTCE
0x8715D ICU
  [0] DTCER[93].DTCE
0x8715E ICU
  [0] DTCER[94].DTCE
0x8715F ICU
  [0] DTCER[95].DTCE
0x87160 ICU
  [0] DTCER[96](WDT,WOVI).DTCE
0x87161 ICU
  [0] DTCER[97].DTCE
0x87162 ICU
  [0] DTCER[98](AD0,ADI0).DTCE
0x87163 ICU
  [0] DTCER[99](AD1,ADI1).DTCE
0x87164 ICU
  [0] DTCER[100].DTCE
0x87165 ICU
  [0] DTCER[101].DTCE
0x87166 ICU
  [0] DTCER[102](S12AD,ADI).DTCE
0x87167 ICU
  [0] DTCER[103].DTCE
0x87168 ICU
  [0] DTCER[104].DTCE
0x87169 ICU
  [0] DTCER[105].DTCE
0x8716A ICU
  [0] DTCER[106].DTCE
0x8716B ICU
  [0] DTCER[107].DTCE
0x8716C ICU
  [0] DTCER[108].DTCE
0x8716D ICU
  [0] DTCER[109].DTCE
0x8716E ICU
  [0] DTCER[110].DTCE
0x8716F ICU
  [0] DTCER[111].DTCE
0x87170 ICU
  [0] DTCER[112].DTCE
0x87171 ICU
  [0] DTCER[113].DTCE
0x87172 ICU
  [0] DTCER[114](MTU0,TGIA0).DTCE
0x87173 ICU
  [0] DTCER[115](MTU0,TGIB0).DTCE
0x87174 ICU
  [0] DTCER[116](MTU0,TGIC0).DTCE
0x87175 ICU
  [0] DTCER[117](MTU0,TGID0).DTCE
0x87176 ICU
  [0] DTCER[118](MTU0,TCIV0).DTCE
0x87177 ICU
  [0] DTCER[119](MTU0,TGIE0).DTCE
0x87178 ICU
  [0] DTCER[120](MTU0,TGIF0).DTCE
0x87179 ICU
  [0] DTCER[121](MTU1,TGIA1).DTCE
0x8717A ICU
  [0] DTCER[122](MTU1,TGIB1).DTCE
0x8717B ICU
  [0] DTCER[123](MTU1,TCIV1).DTCE
0x8717C ICU
  [0] DTCER[124](MTU1,TCIU1).DTCE
0x8717D ICU
  [0] DTCER[125](MTU2,TGIA2).DTCE
0x8717E ICU
  [0] DTCER[126](MTU2,TGIB2).DTCE
0x8717F ICU
  [0] DTCER[127](MTU2,TCIV2).DTCE
0x87180 ICU
  [0] DTCER[128](MTU2,TCIU2).DTCE
0x87181 ICU
  [0] DTCER[129](MTU3,TGIA3).DTCE
0x87182 ICU
  [0] DTCER[130](MTU3,TGIB3).DTCE
0x87183 ICU
  [0] DTCER[131](MTU3,TGIC3).DTCE
0x87184 ICU
  [0] DTCER[132](MTU3,TGID3).DTCE
0x87185 ICU
  [0] DTCER[133](MTU3,TCIV3).DTCE
0x87186 ICU
  [0] DTCER[134](MTU4,TGIA4).DTCE
0x87187 ICU
  [0] DTCER[135](MTU4,TGIB4).DTCE
0x87188 ICU
  [0] DTCER[136](MTU4,TGIC4).DTCE
0x87189 ICU
  [0] DTCER[137](MTU4,TGID4).DTCE
0x8718A ICU
  [0] DTCER[138](MTU4,TCIV4).DTCE
0x8718B ICU
  [0] DTCER[139](MTU5,TGIU5).DTCE
0x8718C ICU
  [0] DTCER[140](MTU5,TGIV5).DTCE
0x8718D ICU
  [0] DTCER[141](MTU5,TGIW5).DTCE
0x8718E ICU
  [0] DTCER[142](MTU6,TGIA6).DTCE
0x8718F ICU
  [0] DTCER[143](MTU6,TGIB6).DTCE
0x87190 ICU
  [0] DTCER[144](MTU6,TGIC6).DTCE
0x87191 ICU
  [0] DTCER[145](MTU6,TGID6).DTCE
0x87192 ICU
  [0] DTCER[146](MTU6,TCIV6).DTCE
0x87193 ICU
  [0] DTCER[147](MTU6,TGIE6).DTCE
0x87194 ICU
  [0] DTCER[148](MTU6,TGIF6).DTCE
0x87195 ICU
  [0] DTCER[149](MTU7,TGIA7).DTCE
0x87196 ICU
  [0] DTCER[150](MTU7,TGIB7).DTCE
0x87197 ICU
  [0] DTCER[151](MTU7,TCIV7).DTCE
0x87198 ICU
  [0] DTCER[152](MTU7,TCIU7).DTCE
0x87199 ICU
  [0] DTCER[153](MTU8,TGIA8).DTCE
0x8719A ICU
  [0] DTCER[154](MTU8,TGIB8).DTCE
0x8719B ICU
  [0] DTCER[155](MTU8,TCIV8).DTCE
0x8719C ICU
  [0] DTCER[156](MTU8,TCIU8).DTCE
0x8719D ICU
  [0] DTCER[157](MTU9,TGIA9).DTCE
0x8719E ICU
  [0] DTCER[158](MTU9,TGIB9).DTCE
0x8719F ICU
  [0] DTCER[159](MTU9,TGIC9).DTCE
0x871A0 ICU
  [0] DTCER[160](MTU9,TGID9).DTCE
0x871A1 ICU
  [0] DTCER[161](MTU9,TCIV9).DTCE
0x871A2 ICU
  [0] DTCER[162](MTU10,TGIA10).DTCE
0x871A3 ICU
  [0] DTCER[163](MTU10,TGIB10).DTCE
0x871A4 ICU
  [0] DTCER[164](MTU10,TGIC10).DTCE
0x871A5 ICU
  [0] DTCER[165](MTU10,TGID10).DTCE
0x871A6 ICU
  [0] DTCER[166](MTU10,TCIV10).DTCE
0x871A7 ICU
  [0] DTCER[167](MTU11,TGIU11).DTCE
0x871A8 ICU
  [0] DTCER[168](MTU11,TGIV11).DTCE
0x871A9 ICU
  [0] DTCER[169](MTU11,TGIW11).DTCE
0x871AA ICU
  [0] DTCER[170](POE,OEI1).DTCE
0x871AB ICU
  [0] DTCER[171](POE,OEI2).DTCE
0x871AC ICU
  [0] DTCER[172](POE,OEI3).DTCE
0x871AD ICU
  [0] DTCER[173](POE,OEI4).DTCE
0x871AE ICU
  [0] DTCER[174](TMR0,CMIA0).DTCE
0x871AF ICU
  [0] DTCER[175](TMR0,CMIB0).DTCE
0x871B0 ICU
  [0] DTCER[176](TMR0,OVI0).DTCE
0x871B1 ICU
  [0] DTCER[177](TMR1,CMIA1).DTCE
0x871B2 ICU
  [0] DTCER[178](TMR1,CMIB1).DTCE
0x871B3 ICU
  [0] DTCER[179](TMR1,OVI1).DTCE
0x871B4 ICU
  [0] DTCER[180](TMR2,CMIA2).DTCE
0x871B5 ICU
  [0] DTCER[181](TMR2,CMIB2).DTCE
0x871B6 ICU
  [0] DTCER[182](TMR2,OVI2).DTCE
0x871B7 ICU
  [0] DTCER[183](TMR3,CMIA3).DTCE
0x871B8 ICU
  [0] DTCER[184](TMR3,CMIB3).DTCE
0x871B9 ICU
  [0] DTCER[185](TMR3,OVI3).DTCE
0x871BA ICU
  [0] DTCER[186].DTCE
0x871BB ICU
  [0] DTCER[187].DTCE
0x871BC ICU
  [0] DTCER[188].DTCE
0x871BD ICU
  [0] DTCER[189].DTCE
0x871BE ICU
  [0] DTCER[190].DTCE
0x871BF ICU
  [0] DTCER[191].DTCE
0x871C0 ICU
  [0] DTCER[192].DTCE
0x871C1 ICU
  [0] DTCER[193].DTCE
0x871C2 ICU
  [0] DTCER[194].DTCE
0x871C3 ICU
  [0] DTCER[195].DTCE
0x871C4 ICU
  [0] DTCER[196].DTCE
0x871C5 ICU
  [0] DTCER[197].DTCE
0x871C6 ICU
  [0] DTCER[198](DMAC,DMAC0I).DTCE
0x871C7 ICU
  [0] DTCER[199](DMAC,DMAC1I).DTCE
0x871C8 ICU
  [0] DTCER[200](DMAC,DMAC2I).DTCE
0x871C9 ICU
  [0] DTCER[201](DMAC,DMAC3I).DTCE
0x871CA ICU
  [0] DTCER[202](EXDMAC,EXDMAC0I).DTCE
0x871CB ICU
  [0] DTCER[203](EXDMAC,EXDMAC1I).DTCE
0x871CC ICU
  [0] DTCER[204].DTCE
0x871CD ICU
  [0] DTCER[205].DTCE
0x871CE ICU
  [0] DTCER[206].DTCE
0x871CF ICU
  [0] DTCER[207].DTCE
0x871D0 ICU
  [0] DTCER[208].DTCE
0x871D1 ICU
  [0] DTCER[209].DTCE
0x871D2 ICU
  [0] DTCER[210].DTCE
0x871D3 ICU
  [0] DTCER[211].DTCE
0x871D4 ICU
  [0] DTCER[212].DTCE
0x871D5 ICU
  [0] DTCER[213].DTCE
0x871D6 ICU
  [0] DTCER[214](SCI0,ERI0).DTCE
0x871D7 ICU
  [0] DTCER[215](SCI0,RXI0).DTCE
0x871D8 ICU
  [0] DTCER[216](SCI0,TXI0).DTCE
0x871D9 ICU
  [0] DTCER[217](SCI0,TEI0).DTCE
0x871DA ICU
  [0] DTCER[218](SCI1,ERI1).DTCE
0x871DB ICU
  [0] DTCER[219](SCI1,RXI1).DTCE
0x871DC ICU
  [0] DTCER[220](SCI1,TXI1).DTCE
0x871DD ICU
  [0] DTCER[221](SCI1,TEI1).DTCE
0x871DE ICU
  [0] DTCER[222](SCI2,ERI2).DTCE
0x871DF ICU
  [0] DTCER[223](SCI2,RXI2).DTCE
0x871E0 ICU
  [0] DTCER[224](SCI2,TXI2).DTCE
0x871E1 ICU
  [0] DTCER[225](SCI2,TEI2).DTCE
0x871E2 ICU
  [0] DTCER[226](SCI3,ERI3).DTCE
0x871E3 ICU
  [0] DTCER[227](SCI3,RXI3).DTCE
0x871E4 ICU
  [0] DTCER[228](SCI3,TXI3).DTCE
0x871E5 ICU
  [0] DTCER[229](SCI3,TEI3).DTCE
0x871E6 ICU
  [0] DTCER[230].DTCE
0x871E7 ICU
  [0] DTCER[231].DTCE
0x871E8 ICU
  [0] DTCER[232].DTCE
0x871E9 ICU
  [0] DTCER[233].DTCE
0x871EA ICU
  [0] DTCER[234](SCI5,ERI5).DTCE
0x871EB ICU
  [0] DTCER[235](SCI5,RXI5).DTCE
0x871EC ICU
  [0] DTCER[236](SCI5,TXI5).DTCE
0x871ED ICU
  [0] DTCER[237](SCI5,TEI5).DTCE
0x871EE ICU
  [0] DTCER[238](SCI6,ERI6).DTCE
0x871EF ICU
  [0] DTCER[239](SCI6,RXI6).DTCE
0x871F0 ICU
  [0] DTCER[240](SCI6,TXI6).DTCE
0x871F1 ICU
  [0] DTCER[241](SCI6,TEI6).DTCE
0x871F2 ICU
  [0] DTCER[242].DTCE
0x871F3 ICU
  [0] DTCER[243].DTCE
0x871F4 ICU
  [0] DTCER[244].DTCE
0x871F5 ICU
  [0] DTCER[245].DTCE
0x871F6 ICU
  [0] DTCER[246](RIIC0,ICEEI0).DTCE
0x871F7 ICU
  [0] DTCER[247](RIIC0,ICRXI0).DTCE
0x871F8 ICU
  [0] DTCER[248](RIIC0,ICTXI0).DTCE
0x871F9 ICU
  [0] DTCER[249](RIIC0,ICTEI0).DTCE
0x871FA ICU
  [0] DTCER[250](RIIC1,ICEEI1).DTCE
0x871FB ICU
  [0] DTCER[251](RIIC1,ICRXI1).DTCE
0x871FC ICU
  [0] DTCER[252](RIIC1,ICTXI1).DTCE
0x87200 ICU
  [n] IER[0].IEN{n} (n=0..7)
0x87201 ICU
  [n] IER[1].IEN{n} (n=0..7)
0x87202 ICU
  [7] IER[2].IEN7(FCU,FRDYI), [6] IER[2].IEN6, [5] IER[2].IEN5(FCU,FIFERR), [n] IER[2].IEN{n} (n=1..4), [0] IER[2].IEN0(BSC,BUSERR)
0x87203 ICU
  [n] IER[3].IEN{n}(CMT{n-4},CMI{n-4}) (n=4..7), [3] IER[3].IEN3(ICU,SWINT), [2] IER[3].IEN2, [1] IER[3].IEN1, [0] IER[3].IEN0
0x87204 ICU
  [7] IER[4].IEN7, [6] IER[4].IEN6(USB0,USBI0), [5] IER[4].IEN5(USB0,D1FIFO0), [4] IER[4].IEN4(USB0,D0FIFO0), [3] IER[4].IEN3, [2] IER[4].IEN2, [1] IER[4].IEN1, [0] IER[4].IEN0(ETHER,EINT)
0x87205 ICU
  [7] IER[5].IEN7(RSPI0,SPII0), [6] IER[5].IEN6(RSPI0,SPTI0), [5] IER[5].IEN5(RSPI0,SPRI0), [4] IER[5].IEN4(RSPI0,SPEI0), [3] IER[5].IEN3, [2] IER[5].IEN2(USB1,USBI1), [1] IER[5].IEN1(USB1,D1FIFO1), [0] IER[5].IEN0(USB1,D0FIFO1)
0x87206 ICU
  [n] IER[6].IEN{n} (n=4..7), [3] IER[6].IEN3(RSPI1,SPII1), [2] IER[6].IEN2(RSPI1,SPTI1), [1] IER[6].IEN1(RSPI1,SPRI1), [0] IER[6].IEN0(RSPI1,SPEI1)
0x87207 ICU
  [7] IER[7].IEN7(RTC,CUP), [6] IER[7].IEN6(RTC,PRD), [5] IER[7].IEN5, [4] IER[7].IEN4(CAN0,TXM0), [3] IER[7].IEN3(CAN0,RXM0), [2] IER[7].IEN2(CAN0,TXF0), [1] IER[7].IEN1(CAN0,RXF0), [0] IER[7].IEN0(CAN0,ERS0)
0x87208 ICU
  [n] IER[8].IEN{n}(ICU,IRQ{n}) (n=0..7)
0x87209 ICU
  [n] IER[9].IEN{n}(ICU,IRQ{n+8}) (n=0..7)
0x8720A ICU
  [n] IER[10].IEN{n} (n=0..7)
0x8720B ICU
  [7] IER[11].IEN7, [6] IER[11].IEN6, [5] IER[11].IEN5, [4] IER[11].IEN4(RTC,ALM), [3] IER[11].IEN3(USB,USBR1), [2] IER[11].IEN2(USB,USBR0), [1] IER[11].IEN1, [0] IER[11].IEN0
0x8720C ICU
  [7] IER[12].IEN7, [6] IER[12].IEN6(S12AD,ADI), [5] IER[12].IEN5, [4] IER[12].IEN4, [3] IER[12].IEN3(AD1,ADI1), [2] IER[12].IEN2(AD0,ADI0), [1] IER[12].IEN1, [0] IER[12].IEN0(WDT,WOVI)
0x8720D ICU
  [n] IER[13].IEN{n} (n=0..7)
0x8720E ICU
  [7] IER[14].IEN7(MTU0,TGIE0), [6] IER[14].IEN6(MTU0,TCIV0), [5] IER[14].IEN5(MTU0,TGID0), [4] IER[14].IEN4(MTU0,TGIC0), [3] IER[14].IEN3(MTU0,TGIB0), [2] IER[14].IEN2(MTU0,TGIA0), [1] IER[14].IEN1, [0] IER[14].IEN0
0x8720F ICU
  [7] IER[15].IEN7(MTU2,TCIV2), [6] IER[15].IEN6(MTU2,TGIB2), [5] IER[15].IEN5(MTU2,TGIA2), [4] IER[15].IEN4(MTU1,TCIU1), [3] IER[15].IEN3(MTU1,TCIV1), [2] IER[15].IEN2(MTU1,TGIB1), [1] IER[15].IEN1(MTU1,TGIA1), [0] IER[15].IEN0(MTU0,TGIF0)
0x87210 ICU
  [7] IER[16].IEN7(MTU4,TGIB4), [6] IER[16].IEN6(MTU4,TGIA4), [5] IER[16].IEN5(MTU3,TCIV3), [4] IER[16].IEN4(MTU3,TGID3), [3] IER[16].IEN3(MTU3,TGIC3), [2] IER[16].IEN2(MTU3,TGIB3), [1] IER[16].IEN1(MTU3,TGIA3), [0] IER[16].IEN0(MTU2,TCIU2)
0x87211 ICU
  [7] IER[17].IEN7(MTU6,TGIB6), [6] IER[17].IEN6(MTU6,TGIA6), [5] IER[17].IEN5(MTU5,TGIW5), [4] IER[17].IEN4(MTU5,TGIV5), [3] IER[17].IEN3(MTU5,TGIU5), [2] IER[17].IEN2(MTU4,TCIV4), [1] IER[17].IEN1(MTU4,TGID4), [0] IER[17].IEN0(MTU4,TGIC4)
0x87212 ICU
  [7] IER[18].IEN7(MTU7,TCIV7), [6] IER[18].IEN6(MTU7,TGIB7), [5] IER[18].IEN5(MTU7,TGIA7), [4] IER[18].IEN4(MTU6,TGIF6), [3] IER[18].IEN3(MTU6,TGIE6), [2] IER[18].IEN2(MTU6,TCIV6), [1] IER[18].IEN1(MTU6,TGID6), [0] IER[18].IEN0(MTU6,TGIC6)
0x87213 ICU
  [7] IER[19].IEN7(MTU9,TGIC9), [6] IER[19].IEN6(MTU9,TGIB9), [5] IER[19].IEN5(MTU9,TGIA9), [4] IER[19].IEN4(MTU8,TCIU8), [3] IER[19].IEN3(MTU8,TCIV8), [2] IER[19].IEN2(MTU8,TGIB8), [1] IER[19].IEN1(MTU8,TGIA8), [0] IER[19].IEN0(MTU7,TCIU7)
0x87214 ICU
  [7] IER[20].IEN7(MTU11,TGIU11), [6] IER[20].IEN6(MTU10,TCIV10), [5] IER[20].IEN5(MTU10,TGID10), [4] IER[20].IEN4(MTU10,TGIC10), [3] IER[20].IEN3(MTU10,TGIB10), [2] IER[20].IEN2(MTU10,TGIA10), [1] IER[20].IEN1(MTU9,TCIV9), [0] IER[20].IEN0(MTU9,TGID9)
0x87215 ICU
  [7] IER[21].IEN7(TMR0,CMIB0), [6] IER[21].IEN6(TMR0,CMIA0), [n] IER[21].IEN{n}(POE,OEI{n-1}) (n=2..5), [1] IER[21].IEN1(MTU11,TGIW11), [0] IER[21].IEN0(MTU11,TGIV11)
0x87216 ICU
  [7] IER[22].IEN7(TMR3,CMIA3), [6] IER[22].IEN6(TMR2,OVI2), [5] IER[22].IEN5(TMR2,CMIB2), [4] IER[22].IEN4(TMR2,CMIA2), [3] IER[22].IEN3(TMR1,OVI1), [2] IER[22].IEN2(TMR1,CMIB1), [1] IER[22].IEN1(TMR1,CMIA1), [0] IER[22].IEN0(TMR0,OVI0)
0x87217 ICU
  [n] IER[23].IEN{n} (n=2..7), [1] IER[23].IEN1(TMR3,OVI3), [0] IER[23].IEN0(TMR3,CMIB3)
0x87218 ICU
  [7] IER[24].IEN7(DMAC,DMAC1I), [6] IER[24].IEN6(DMAC,DMAC0I), [n] IER[24].IEN{n} (n=0..5)
0x87219 ICU
  [n] IER[25].IEN{n} (n=4..7), [3] IER[25].IEN3(EXDMAC,EXDMAC1I), [2] IER[25].IEN2(EXDMAC,EXDMAC0I), [1] IER[25].IEN1(DMAC,DMAC3I), [0] IER[25].IEN0(DMAC,DMAC2I)
